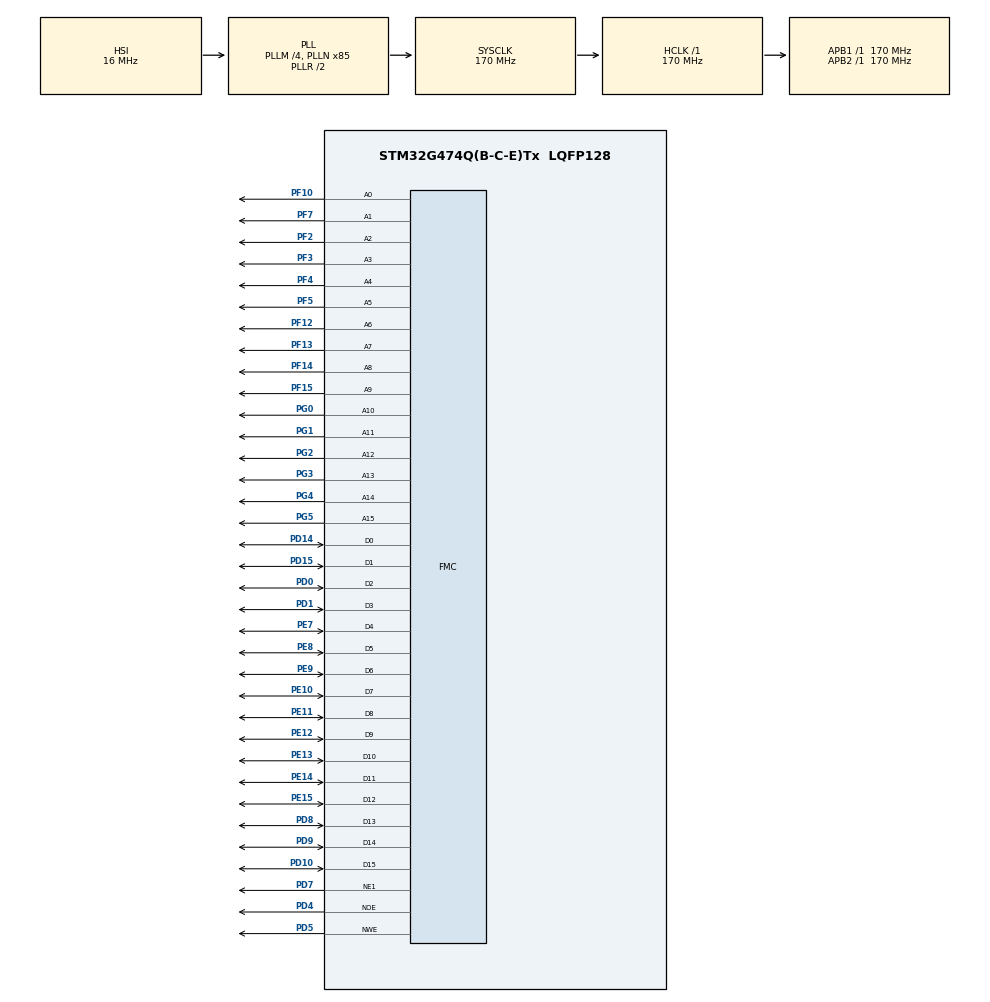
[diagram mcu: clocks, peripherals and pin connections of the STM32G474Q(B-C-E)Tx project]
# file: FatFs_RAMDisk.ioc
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FATFS.BOARD_NAME=stm32g474e
FATFS.SRAM_BSP_CODE=1
FATFS._CODE_PAGE=850
FATFS._FS_EXFAT=0
FATFS._FS_LOCK=2
FATFS._FS_MINIMIZE=0
FATFS._FS_NOFSINFO=0
FATFS._FS_NORTC=0
FATFS._FS_READONLY=0
FATFS._FS_REENTRANT=0
FATFS._FS_RPATH=0
FATFS._FS_TIMEOUT=1000
FATFS._FS_TINY=0
FATFS._HSRAM=hsram1
FATFS._LFN_UNICODE=0
FATFS._MAX_LFN=255
FATFS._MAX_SS=512
FATFS._MIN_SS=512
FATFS._MULTI_PARTITION=0
FATFS._STRF_ENCODE=3
FATFS._USE_CHMOD=0
FATFS._USE_EXPAND=0
FATFS._USE_FASTSEEK=1
FATFS._USE_FIND=0
FATFS._USE_FORWARD=0
FATFS._USE_LABEL=0
FATFS._USE_LFN=0
FATFS._USE_MKFS=1
FATFS._USE_STRFUNC=2
FATFS._USE_TRIM=0
FATFS._VOLUMES=1
FMC.AddressSetupTime1=15
FMC.BusTurnAroundDuration1=15
FMC.DataHoldTime1=0
FMC.DataSetupTime1=255
FMC.ExtendedMode1=FMC_EXTENDED_MODE_DISABLE
FMC.MemoryType1=FMC_MEMORY_TYPE_SRAM
FMC.NSBank1=FMC_NORSRAM_BANK1
FMC.WriteFifo1=FMC_WRITE_FIFO_ENABLE
FMC.WriteOperation1=FMC_WRITE_OPERATION_DISABLE
Mcu.Family=STM32G4
Mcu.Name=STM32G474Q(B-C-E)Tx
Mcu.Package=LQFP128
NVIC.PriorityGroup=NVIC_PRIORITYGROUP_4
PD0.Signal=FMC_D2_DA2
PD1.Signal=FMC_D3_DA3
PD10.Signal=FMC_D15_DA15
PD14.Signal=FMC_D0_DA0
PD15.Signal=FMC_D1_DA1
PD4.Signal=FMC_NOE
PD5.Signal=FMC_NWE
PD7.Mode=NorPsramChipSelect1_1
PD7.Signal=FMC_NE1
PD8.Signal=FMC_D13_DA13
PD9.Signal=FMC_D14_DA14
PE10.Signal=FMC_D7_DA7
PE11.Signal=FMC_D8_DA8
PE12.Signal=FMC_D9_DA9
PE13.Signal=FMC_D10_DA10
PE14.Signal=FMC_D11_DA11
PE15.Signal=FMC_D12_DA12
PE7.Signal=FMC_D4_DA4
PE8.Signal=FMC_D5_DA5
PE9.Signal=FMC_D6_DA6
PF10.Signal=FMC_A0
PF12.Signal=FMC_A6
PF13.Signal=FMC_A7
PF14.Signal=FMC_A8
PF15.Signal=FMC_A9
PF2.Signal=FMC_A2
PF3.Signal=FMC_A3
PF4.Signal=FMC_A4
PF5.Signal=FMC_A5
PF7.Signal=FMC_A1
PG0.Signal=FMC_A10
PG1.Signal=FMC_A11
PG2.Signal=FMC_A12
PG3.Signal=FMC_A13
PG4.Signal=FMC_A14
PG5.Signal=FMC_A15
ProjectManager.HeapSize=0x400
ProjectManager.StackSize=0x400
ProjectManager.TargetToolchain=EWARM V8.32
RCC.ADC12Freq_Value=170000000
RCC.ADC345Freq_Value=170000000
RCC.AHBFreq_Value=170000000
RCC.APB1Freq_Value=170000000
RCC.APB1TimFreq_Value=170000000
RCC.APB2Freq_Value=170000000
RCC.APB2TimFreq_Value=170000000
RCC.CortexFreq_Value=170000000
RCC.EXTERNAL_CLOCK_VALUE=12288000
RCC.HCLKFreq_Value=170000000
RCC.HSE_VALUE=24000000
RCC.HSI48_VALUE=48000000
RCC.HSI_VALUE=16000000
RCC.LSE_VALUE=32768
RCC.PLLM=RCC_PLLM_DIV4
RCC.PLLN=85
RCC.SYSCLKFreq_VALUE=170000000
RCC.SYSCLKSource=RCC_SYSCLKSOURCE_PLLCLK
RCC.USBFreq_Value=170000000
RCC.VCOOutputFreq_Value=340000000
SH.FMC_A0.0=FMC_A0,16b-a1
SH.FMC_A1.0=FMC_A1,16b-a1
SH.FMC_A10.0=FMC_A10,16b-a1
SH.FMC_A11.0=FMC_A11,16b-a1
SH.FMC_A12.0=FMC_A12,16b-a1
SH.FMC_A13.0=FMC_A13,16b-a1
SH.FMC_A14.0=FMC_A14,16b-a1
SH.FMC_A15.0=FMC_A15,16b-a1
SH.FMC_A2.0=FMC_A2,16b-a1
SH.FMC_A3.0=FMC_A3,16b-a1
SH.FMC_A4.0=FMC_A4,16b-a1
SH.FMC_A5.0=FMC_A5,16b-a1
SH.FMC_A6.0=FMC_A6,16b-a1
SH.FMC_A7.0=FMC_A7,16b-a1
SH.FMC_A8.0=FMC_A8,16b-a1
SH.FMC_A9.0=FMC_A9,16b-a1
SH.FMC_D0_DA0.0=FMC_D0,16b-d1
SH.FMC_D10_DA10.0=FMC_D10,16b-d1
SH.FMC_D11_DA11.0=FMC_D11,16b-d1
SH.FMC_D12_DA12.0=FMC_D12,16b-d1
SH.FMC_D13_DA13.0=FMC_D13,16b-d1
SH.FMC_D14_DA14.0=FMC_D14,16b-d1
SH.FMC_D15_DA15.0=FMC_D15,16b-d1
SH.FMC_D1_DA1.0=FMC_D1,16b-d1
SH.FMC_D2_DA2.0=FMC_D2,16b-d1
SH.FMC_D3_DA3.0=FMC_D3,16b-d1
SH.FMC_D4_DA4.0=FMC_D4,16b-d1
SH.FMC_D5_DA5.0=FMC_D5,16b-d1
SH.FMC_D6_DA6.0=FMC_D6,16b-d1
SH.FMC_D7_DA7.0=FMC_D7,16b-d1
SH.FMC_D8_DA8.0=FMC_D8,16b-d1
SH.FMC_D9_DA9.0=FMC_D9,16b-d1
SH.FMC_NOE.0=FMC_NOE,Sram1
SH.FMC_NWE.0=FMC_NWE,Sram1
VP_FATFS_VS_SRAM.Mode=SRAM
VP_SYS_VS_DBSignals.Mode=DisableDeadBatterySignals
board=custom

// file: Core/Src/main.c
/* USER CODE BEGIN Header */
/**
  ******************************************************************************
  * @file    FatFs/FatFs_RAMDisk/Core/Src/main.c
  * @author  MCD Application Team
  * @brief   Main program body
  *          This sample code shows how to use FatFs with RAM disk drive.
  ******************************************************************************
  * @attention
  *
  * Copyright (c) 2019 STMicroelectronics.
  * All rights reserved.
  *
  * This software is licensed under terms that can be found in the LICENSE file
  * in the root directory of this software component.
  * If no LICENSE file comes with this software, it is provided AS-IS.
  *
  ******************************************************************************
  */
/* USER CODE END Header */
#include "main.h"
#include "app_fatfs.h"

SRAM_HandleTypeDef hsram1;

/* USER CODE BEGIN PV */
int32_t ProcessStatus = 0;
/* USER CODE END PV */

void SystemClock_Config(void);
static void MX_GPIO_Init(void);
static void MX_FMC_Init(void);

int main(void)
{

  /* MCU Configuration--------------------------------------------------------*/

  /* Reset of all peripherals, Initializes the Flash interface and the Systick. */
  HAL_Init();

  /* Configure the system clock */
  SystemClock_Config();

  /* USER CODE BEGIN SysInit */
  /* Configure LED_OK and LED_ERROR */
  BSP_LED_Init(LED_OK);
  BSP_LED_Init(LED_ERROR);

  /* USER CODE END SysInit */

  /* Initialize all configured peripherals */
  MX_GPIO_Init();
  MX_FMC_Init();
  if (MX_FATFS_Init() != APP_OK) {
    Error_Handler();
  }

  /* Infinite loop */
  /* USER CODE BEGIN WHILE */
  while (1)
  {
    ProcessStatus = MX_FATFS_Process();
    /* Call middleware background task */
    if (ProcessStatus == APP_ERROR)
    {
      Error_Handler();
    }
    else
    {
      BSP_LED_Off(LED_ERROR);
      BSP_LED_On(LED_OK);
    }

    /* USER CODE END WHILE */

  }
}

void SystemClock_Config(void)
{
  RCC_OscInitTypeDef RCC_OscInitStruct = {0};
  RCC_ClkInitTypeDef RCC_ClkInitStruct = {0};

  /** Configure the main internal regulator output voltage
  */
  HAL_PWREx_ControlVoltageScaling(PWR_REGULATOR_VOLTAGE_SCALE1_BOOST);

  /** Initializes the RCC Oscillators according to the specified parameters
  * in the RCC_OscInitTypeDef structure.
  */
  RCC_OscInitStruct.OscillatorType = RCC_OSCILLATORTYPE_HSI;
  RCC_OscInitStruct.HSIState = RCC_HSI_ON;
  RCC_OscInitStruct.HSICalibrationValue = RCC_HSICALIBRATION_DEFAULT;
  RCC_OscInitStruct.PLL.PLLState = RCC_PLL_ON;
  RCC_OscInitStruct.PLL.PLLSource = RCC_PLLSOURCE_HSI;
  RCC_OscInitStruct.PLL.PLLM = RCC_PLLM_DIV4;
  RCC_OscInitStruct.PLL.PLLN = 85;
  RCC_OscInitStruct.PLL.PLLP = RCC_PLLP_DIV2;
  RCC_OscInitStruct.PLL.PLLQ = RCC_PLLQ_DIV2;
  RCC_OscInitStruct.PLL.PLLR = RCC_PLLR_DIV2;
  if (HAL_RCC_OscConfig(&RCC_OscInitStruct) != HAL_OK)
  {
    Error_Handler();
  }

  /** Initializes the CPU, AHB and APB buses clocks
  */
  RCC_ClkInitStruct.ClockType = RCC_CLOCKTYPE_HCLK|RCC_CLOCKTYPE_SYSCLK
                              |RCC_CLOCKTYPE_PCLK1|RCC_CLOCKTYPE_PCLK2;
  RCC_ClkInitStruct.SYSCLKSource = RCC_SYSCLKSOURCE_PLLCLK;
  RCC_ClkInitStruct.AHBCLKDivider = RCC_SYSCLK_DIV1;
  RCC_ClkInitStruct.APB1CLKDivider = RCC_HCLK_DIV1;
  RCC_ClkInitStruct.APB2CLKDivider = RCC_HCLK_DIV1;

  if (HAL_RCC_ClockConfig(&RCC_ClkInitStruct, FLASH_LATENCY_4) != HAL_OK)
  {
    Error_Handler();
  }
}

/* FMC initialization function */
static void MX_FMC_Init(void)
{

  FMC_NORSRAM_TimingTypeDef Timing = {0};

  /** Perform the SRAM1 memory initialization sequence
  */
  hsram1.Instance = FMC_NORSRAM_DEVICE;
  hsram1.Extended = FMC_NORSRAM_EXTENDED_DEVICE;
  /* hsram1.Init */
  hsram1.Init.NSBank = FMC_NORSRAM_BANK1;
  hsram1.Init.DataAddressMux = FMC_DATA_ADDRESS_MUX_DISABLE;
  hsram1.Init.MemoryType = FMC_MEMORY_TYPE_SRAM;
  hsram1.Init.MemoryDataWidth = FMC_NORSRAM_MEM_BUS_WIDTH_16;
  hsram1.Init.BurstAccessMode = FMC_BURST_ACCESS_MODE_DISABLE;
  hsram1.Init.WaitSignalPolarity = FMC_WAIT_SIGNAL_POLARITY_LOW;
  hsram1.Init.WaitSignalActive = FMC_WAIT_TIMING_BEFORE_WS;
  hsram1.Init.WriteOperation = FMC_WRITE_OPERATION_DISABLE;
  hsram1.Init.WaitSignal = FMC_WAIT_SIGNAL_DISABLE;
  hsram1.Init.ExtendedMode = FMC_EXTENDED_MODE_DISABLE;
  hsram1.Init.AsynchronousWait = FMC_ASYNCHRONOUS_WAIT_DISABLE;
  hsram1.Init.WriteBurst = FMC_WRITE_BURST_DISABLE;
  hsram1.Init.ContinuousClock = FMC_CONTINUOUS_CLOCK_SYNC_ONLY;
  hsram1.Init.WriteFifo = FMC_WRITE_FIFO_ENABLE;
  hsram1.Init.NBLSetupTime = 0;
  hsram1.Init.PageSize = FMC_PAGE_SIZE_NONE;
  hsram1.Init.MaxChipSelectPulse = DISABLE;
  /* Timing */
  Timing.AddressSetupTime = 15;
  Timing.AddressHoldTime = 15;
  Timing.DataSetupTime = 255;
  Timing.DataHoldTime = 0;
  Timing.BusTurnAroundDuration = 15;
  Timing.CLKDivision = 16;
  Timing.DataLatency = 17;
  Timing.AccessMode = FMC_ACCESS_MODE_A;
  /* ExtTiming */

  if (HAL_SRAM_Init(&hsram1, &Timing, NULL) != HAL_OK)
  {
    Error_Handler( );
  }

}

static void MX_GPIO_Init(void)
{

  /* GPIO Ports Clock Enable */
  __HAL_RCC_GPIOF_CLK_ENABLE();
  __HAL_RCC_GPIOE_CLK_ENABLE();
  __HAL_RCC_GPIOD_CLK_ENABLE();
  __HAL_RCC_GPIOG_CLK_ENABLE();

}

void Error_Handler(void)
{
  /* USER CODE BEGIN Error_Handler_Debug */
  /* User can add his own implementation to report the HAL error return state */
  BSP_LED_Off(LED_OK);
  BSP_LED_On(LED_ERROR);
  while(1)
  {
  }
  /* USER CODE END Error_Handler_Debug */
}
